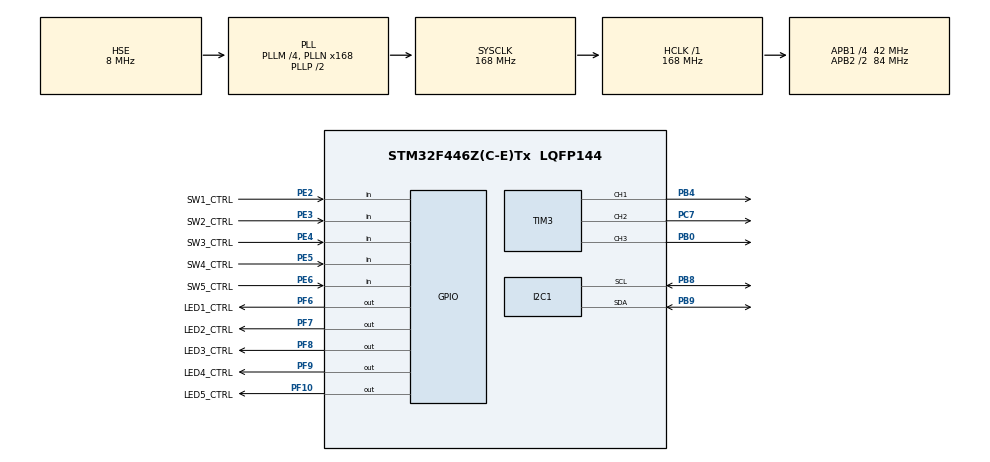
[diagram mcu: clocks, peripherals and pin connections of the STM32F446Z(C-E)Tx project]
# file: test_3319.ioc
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Mcu.Family=STM32F4
Mcu.Name=STM32F446Z(C-E)Tx
Mcu.Package=LQFP144
NVIC.PriorityGroup=NVIC_PRIORITYGROUP_4
PB0.Signal=S_TIM3_CH3
PB4.Signal=S_TIM3_CH1
PB8.Mode=I2C
PB8.Signal=I2C1_SCL
PB9.Mode=I2C
PB9.Signal=I2C1_SDA
PC7.Signal=S_TIM3_CH2
PE2.GPIO_Label=SW1_CTRL
PE2.Signal=GPIO_Input
PE3.GPIO_Label=SW2_CTRL
PE3.Signal=GPIO_Input
PE4.GPIO_Label=SW3_CTRL
PE4.Signal=GPIO_Input
PE5.GPIO_Label=SW4_CTRL
PE5.Signal=GPIO_Input
PE6.GPIO_Label=SW5_CTRL
PE6.Signal=GPIO_Input
PF10.GPIO_Label=LED5_CTRL
PF10.Signal=GPIO_Output
PF6.GPIO_Label=LED1_CTRL
PF6.Signal=GPIO_Output
PF7.GPIO_Label=LED2_CTRL
PF7.Signal=GPIO_Output
PF8.GPIO_Label=LED3_CTRL
PF8.Signal=GPIO_Output
PF9.GPIO_Label=LED4_CTRL
PF9.Signal=GPIO_Output
PH0-OSC_IN.Mode=HSE-External-Oscillator
PH0-OSC_IN.Signal=RCC_OSC_IN
PH1-OSC_OUT.Mode=HSE-External-Oscillator
PH1-OSC_OUT.Signal=RCC_OSC_OUT
ProjectManager.HeapSize=0x200
ProjectManager.StackSize=0x400
ProjectManager.TargetToolchain=MDK-ARM V5
RCC.AHBFreq_Value=168000000
RCC.APB1CLKDivider=RCC_HCLK_DIV4
RCC.APB1Freq_Value=42000000
RCC.APB1TimFreq_Value=84000000
RCC.APB2CLKDivider=RCC_HCLK_DIV2
RCC.APB2Freq_Value=84000000
RCC.APB2TimFreq_Value=168000000
RCC.CortexFreq_Value=168000000
RCC.HCLKFreq_Value=168000000
RCC.HSE_VALUE=8000000
RCC.PLLM=4
RCC.PLLN=168
RCC.PLLSourceVirtual=RCC_PLLSOURCE_HSE
RCC.SYSCLKFreq_VALUE=168000000
RCC.SYSCLKSource=RCC_SYSCLKSOURCE_PLLCLK
RCC.USBFreq_Value=168000000
RCC.VCOOutputFreq_Value=336000000
SH.S_TIM3_CH1.0=TIM3_CH1,PWM Generation1 CH1
SH.S_TIM3_CH2.0=TIM3_CH2,PWM Generation2 CH2
SH.S_TIM3_CH3.0=TIM3_CH3,PWM Generation3 CH3
TIM3.Channel-PWM\ Generation1\ CH1=TIM_CHANNEL_1
TIM3.Channel-PWM\ Generation2\ CH2=TIM_CHANNEL_2
TIM3.Channel-PWM\ Generation3\ CH3=TIM_CHANNEL_3
board=custom

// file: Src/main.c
/* USER CODE BEGIN Header */
/**
  ******************************************************************************
  * @file           : main.c
  * @brief          : Main program body
  ******************************************************************************
  * @attention
  *
  * <h2><center>&copy; Copyright (c) 2020 STMicroelectronics.
  * All rights reserved.</center></h2>
  *
  * This software component is licensed by ST under BSD 3-Clause license,
  * the "License"; You may not use this file except in compliance with the
  * License. You may obtain a copy of the License at:
  *                        opensource.org/licenses/BSD-3-Clause
  *
  ******************************************************************************
  */
/* USER CODE END Header */

#include "main.h"
#include "EMbed_GPIO_General.h"
#include "I2C1_PCA9535A_FND.h"
#include "TIM3_RGB_LED.h"

I2C_HandleTypeDef hi2c1;

TIM_HandleTypeDef htim3;

void SystemClock_Config(void);
static void MX_GPIO_Init(void);
static void MX_I2C1_Init(void);
static void MX_TIM3_Init(void);
void HAL_TIM_MspPostInit(TIM_HandleTypeDef *htim);

/* USER CODE BEGIN 0 */
TICK_TypeDef hsystick;
/* USER CODE END 0 */

int main(void)
{

  /* MCU Configuration--------------------------------------------------------*/

  /* Reset of all peripherals, Initializes the Flash interface and the Systick. */
  HAL_Init();

  /* Configure the system clock */
  SystemClock_Config();

  /* Initialize all configured peripherals */
  MX_GPIO_Init();
  MX_I2C1_Init();
  MX_TIM3_Init();
  /* USER CODE BEGIN 2 */
	I2C1_PCA9535A_Config();
	//I2C1_FND_TEST();
	// User_PWM_RGB_Test(&htim3);
	WrFND(319);
  /* USER CODE END 2 */

  /* Infinite loop */
  /* USER CODE BEGIN WHILE */
  while (1)
  {
		GPIO_BT_READ(&hButton);
    /* USER CODE END WHILE */

  }
}

void SystemClock_Config(void)
{
  RCC_OscInitTypeDef RCC_OscInitStruct = {0};
  RCC_ClkInitTypeDef RCC_ClkInitStruct = {0};

  /** Configure the main internal regulator output voltage
  */
  __HAL_RCC_PWR_CLK_ENABLE();
  __HAL_PWR_VOLTAGESCALING_CONFIG(PWR_REGULATOR_VOLTAGE_SCALE1);
  /** Initializes the CPU, AHB and APB busses clocks
  */
  RCC_OscInitStruct.OscillatorType = RCC_OSCILLATORTYPE_HSE;
  RCC_OscInitStruct.HSEState = RCC_HSE_ON;
  RCC_OscInitStruct.PLL.PLLState = RCC_PLL_ON;
  RCC_OscInitStruct.PLL.PLLSource = RCC_PLLSOURCE_HSE;
  RCC_OscInitStruct.PLL.PLLM = 4;
  RCC_OscInitStruct.PLL.PLLN = 168;
  RCC_OscInitStruct.PLL.PLLP = RCC_PLLP_DIV2;
  RCC_OscInitStruct.PLL.PLLQ = 2;
  RCC_OscInitStruct.PLL.PLLR = 2;
  if (HAL_RCC_OscConfig(&RCC_OscInitStruct) != HAL_OK)
  {
    Error_Handler();
  }
  /** Initializes the CPU, AHB and APB busses clocks
  */
  RCC_ClkInitStruct.ClockType = RCC_CLOCKTYPE_HCLK|RCC_CLOCKTYPE_SYSCLK
                              |RCC_CLOCKTYPE_PCLK1|RCC_CLOCKTYPE_PCLK2;
  RCC_ClkInitStruct.SYSCLKSource = RCC_SYSCLKSOURCE_PLLCLK;
  RCC_ClkInitStruct.AHBCLKDivider = RCC_SYSCLK_DIV1;
  RCC_ClkInitStruct.APB1CLKDivider = RCC_HCLK_DIV4;
  RCC_ClkInitStruct.APB2CLKDivider = RCC_HCLK_DIV2;

  if (HAL_RCC_ClockConfig(&RCC_ClkInitStruct, FLASH_LATENCY_5) != HAL_OK)
  {
    Error_Handler();
  }
}

static void MX_I2C1_Init(void)
{

  hi2c1.Instance = I2C1;
  hi2c1.Init.ClockSpeed = 100000;
  hi2c1.Init.DutyCycle = I2C_DUTYCYCLE_2;
  hi2c1.Init.OwnAddress1 = 0;
  hi2c1.Init.AddressingMode = I2C_ADDRESSINGMODE_7BIT;
  hi2c1.Init.DualAddressMode = I2C_DUALADDRESS_DISABLE;
  hi2c1.Init.OwnAddress2 = 0;
  hi2c1.Init.GeneralCallMode = I2C_GENERALCALL_DISABLE;
  hi2c1.Init.NoStretchMode = I2C_NOSTRETCH_DISABLE;
  if (HAL_I2C_Init(&hi2c1) != HAL_OK)
  {
    Error_Handler();
  }

}

static void MX_TIM3_Init(void)
{

  TIM_MasterConfigTypeDef sMasterConfig = {0};
  TIM_OC_InitTypeDef sConfigOC = {0};

  htim3.Instance = TIM3;
  htim3.Init.Prescaler = 84-1;
  htim3.Init.CounterMode = TIM_COUNTERMODE_UP;
  htim3.Init.Period = 1000-1;
  htim3.Init.ClockDivision = TIM_CLOCKDIVISION_DIV1;
  htim3.Init.AutoReloadPreload = TIM_AUTORELOAD_PRELOAD_DISABLE;
  if (HAL_TIM_PWM_Init(&htim3) != HAL_OK)
  {
    Error_Handler();
  }
  sMasterConfig.MasterOutputTrigger = TIM_TRGO_RESET;
  sMasterConfig.MasterSlaveMode = TIM_MASTERSLAVEMODE_DISABLE;
  if (HAL_TIMEx_MasterConfigSynchronization(&htim3, &sMasterConfig) != HAL_OK)
  {
    Error_Handler();
  }
  sConfigOC.OCMode = TIM_OCMODE_PWM1;
  sConfigOC.Pulse = 0;
  sConfigOC.OCPolarity = TIM_OCPOLARITY_HIGH;
  sConfigOC.OCFastMode = TIM_OCFAST_DISABLE;
  if (HAL_TIM_PWM_ConfigChannel(&htim3, &sConfigOC, TIM_CHANNEL_1) != HAL_OK)
  {
    Error_Handler();
  }
  if (HAL_TIM_PWM_ConfigChannel(&htim3, &sConfigOC, TIM_CHANNEL_2) != HAL_OK)
  {
    Error_Handler();
  }
  if (HAL_TIM_PWM_ConfigChannel(&htim3, &sConfigOC, TIM_CHANNEL_3) != HAL_OK)
  {
    Error_Handler();
  }
  HAL_TIM_MspPostInit(&htim3);

}

static void MX_GPIO_Init(void)
{
  GPIO_InitTypeDef GPIO_InitStruct = {0};

  /* GPIO Ports Clock Enable */
  __HAL_RCC_GPIOE_CLK_ENABLE();
  __HAL_RCC_GPIOF_CLK_ENABLE();
  __HAL_RCC_GPIOH_CLK_ENABLE();
  __HAL_RCC_GPIOB_CLK_ENABLE();
  __HAL_RCC_GPIOC_CLK_ENABLE();

  /*Configure GPIO pin Output Level */
  HAL_GPIO_WritePin(GPIOF, LED1_CTRL_Pin|LED2_CTRL_Pin|LED3_CTRL_Pin|LED4_CTRL_Pin
                          |LED5_CTRL_Pin, GPIO_PIN_RESET);

  /*Configure GPIO pins : SW1_CTRL_Pin SW2_CTRL_Pin SW3_CTRL_Pin SW4_CTRL_Pin
                           SW5_CTRL_Pin */
  GPIO_InitStruct.Pin = SW1_CTRL_Pin|SW2_CTRL_Pin|SW3_CTRL_Pin|SW4_CTRL_Pin
                          |SW5_CTRL_Pin;
  GPIO_InitStruct.Mode = GPIO_MODE_INPUT;
  GPIO_InitStruct.Pull = GPIO_NOPULL;
  HAL_GPIO_Init(GPIOE, &GPIO_InitStruct);

  /*Configure GPIO pins : LED1_CTRL_Pin LED2_CTRL_Pin LED3_CTRL_Pin LED4_CTRL_Pin
                           LED5_CTRL_Pin */
  GPIO_InitStruct.Pin = LED1_CTRL_Pin|LED2_CTRL_Pin|LED3_CTRL_Pin|LED4_CTRL_Pin
                          |LED5_CTRL_Pin;
  GPIO_InitStruct.Mode = GPIO_MODE_OUTPUT_PP;
  GPIO_InitStruct.Pull = GPIO_NOPULL;
  GPIO_InitStruct.Speed = GPIO_SPEED_FREQ_LOW;
  HAL_GPIO_Init(GPIOF, &GPIO_InitStruct);

}

void Error_Handler(void)
{
}

/************************ (C) COPYRIGHT STMicroelectronics *****END OF FILE****/
